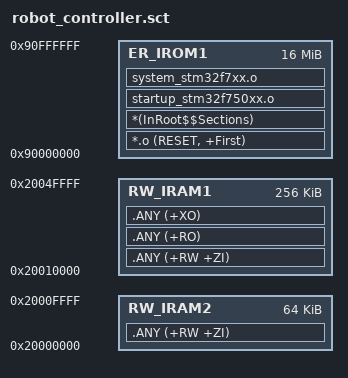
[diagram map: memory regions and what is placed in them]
; *************************************************************
; *** Scatter-Loading Description File generated by uVision ***
; *************************************************************

LR_IROM1 0x90000000 0x01000000  {    ; load region size_region
  ER_IROM1 0x90000000 0x01000000  {  ; load address = execution address
   *.o (RESET, +First)
   *(InRoot$$Sections)
   startup_stm32f750xx.o
   system_stm32f7xx.o
  }
  RW_IRAM1 0x20010000 0x00040000  {  ; RW data
   .ANY (+RW +ZI)
   .ANY (+RO)
   .ANY (+XO)
  }
  RW_IRAM2 0x20000000 0x00010000  {
   .ANY (+RW +ZI)
  }
}

